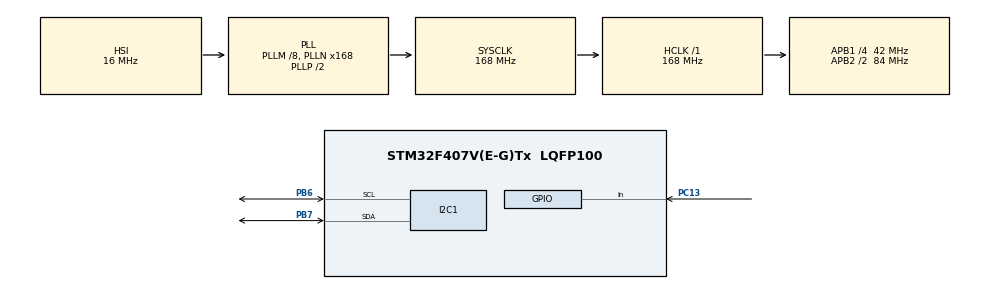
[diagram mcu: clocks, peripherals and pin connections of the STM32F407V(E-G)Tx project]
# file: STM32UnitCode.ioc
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Mcu.Family=STM32F4
Mcu.Name=STM32F407V(E-G)Tx
Mcu.Package=LQFP100
NVIC.PriorityGroup=NVIC_PRIORITYGROUP_4
PA13.Mode=Serial_Wire
PA13.Signal=SYS_JTMS-SWDIO
PA14.Mode=Serial_Wire
PA14.Signal=SYS_JTCK-SWCLK
PB6.Mode=I2C
PB6.Signal=I2C1_SCL
PB7.Mode=I2C
PB7.Signal=I2C1_SDA
PC13-ANTI_TAMP.Signal=GPIO_Input
PC14-OSC32_IN.Mode=LSE-External-Oscillator
PC14-OSC32_IN.Signal=RCC_OSC32_IN
PC15-OSC32_OUT.Mode=LSE-External-Oscillator
PC15-OSC32_OUT.Signal=RCC_OSC32_OUT
PH0-OSC_IN.Mode=HSE-External-Oscillator
PH0-OSC_IN.Signal=RCC_OSC_IN
PH1-OSC_OUT.Mode=HSE-External-Oscillator
PH1-OSC_OUT.Signal=RCC_OSC_OUT
ProjectManager.HeapSize=0x200
ProjectManager.StackSize=0x400
ProjectManager.TargetToolchain=Makefile
RCC.48MHZClocksFreq_Value=48000000
RCC.AHBFreq_Value=168000000
RCC.APB1CLKDivider=RCC_HCLK_DIV4
RCC.APB1Freq_Value=42000000
RCC.APB1TimFreq_Value=84000000
RCC.APB2CLKDivider=RCC_HCLK_DIV2
RCC.APB2Freq_Value=84000000
RCC.APB2TimFreq_Value=168000000
RCC.CortexFreq_Value=168000000
RCC.HCLKFreq_Value=168000000
RCC.HSE_VALUE=25000000
RCC.HSI_VALUE=16000000
RCC.PLLM=8
RCC.PLLN=168
RCC.PLLQ=7
RCC.SYSCLKFreq_VALUE=168000000
RCC.SYSCLKSource=RCC_SYSCLKSOURCE_PLLCLK
RCC.VCOOutputFreq_Value=336000000
board=custom

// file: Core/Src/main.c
/* USER CODE BEGIN Header */
/**
  ******************************************************************************
  * @file           : main.c
  * @brief          : Si5351A 硬件 I2C 驱动验证
  * @details        : 1. 上电后烧写 ClockBuilder Pro 导出配置
  *                      （OUT0=200MHz / OUT1=50MHz / OUT2=10MHz，共用 PLLA）
  *                   2. 之后每 3 秒在 CLK2 上循环切换 10M -> 25M -> 50M -> 100M
  *                      （动态改频走 PLLB，不影响 PLLA 上的 OUT0/OUT1）
  *
  *                   注意：Si5351 模块未连接时 I2C 会超时返回错误，
  *                   err 变量非 0，可用调试器查看定位。
  ******************************************************************************
  */
/* USER CODE END Header */

#include "main.h"
#include "i2c.h"
#include "gpio.h"

/* USER CODE BEGIN Includes */
#include "si5351.h"
/* USER CODE END Includes */

/* USER CODE BEGIN PV */
SI5351_HandleTypeDef hsi5351 = {0};
HAL_StatusTypeDef    err     = HAL_OK;
/* USER CODE END PV */

void SystemClock_Config(void);

int main(void)
{

  /* MCU Configuration--------------------------------------------------------*/

  /* Reset of all peripherals, Initializes the Flash interface and the Systick. */
  HAL_Init();

  /* Configure the system clock */
  SystemClock_Config();

  /* Initialize all configured peripherals */
  MX_GPIO_Init();
  MX_I2C1_Init();
  /* USER CODE BEGIN 2 */

  /* 1. Si5351 基础初始化：关闭所有输出 -> 驱动掉电 -> 晶振负载电容
        （addr/xtal_hz/xtal_load 填 0 用默认：0x60 / 25MHz / 10pF） */
  err = SI5351_Init(&hsi5351, &hi2c1);

  /* 2. 烧写 ClockBuilder Pro 导出配置（Si5351A-RevB-Registers.h）
        = 写 61 条寄存器 + PLL 复位 + 使能输出
        此后 OUT0=200MHz / OUT1=50MHz / OUT2=10MHz 立即输出 */
  if (err == HAL_OK)
      err = SI5351_LoadClockBuilderConfig(&hsi5351);

  /* 模块未连接/通信失败时 err != HAL_OK，停在这里便于调试定位 */
  if (err != HAL_OK)
  {
      while (1) { }
  }

  /* 动态改频演示用的频率表（CLK2 走 PLLB，不影响 PLLA 上的 OUT0/OUT1） */
  const int32_t demo_freq[] = { 10000000, 25000000, 50000000, 100000000 };
  uint8_t idx = 0;

  /* USER CODE END 2 */

  /* Infinite loop */
  while (1)
  {

    /* USER CODE BEGIN 3 */
      /* 3. 每 3 秒在 CLK2 上切换频率：10M -> 25M -> 50M -> 100M -> ... */
      err = SI5351_SetupCLK2(&hsi5351, demo_freq[idx], SI5351_DRIVE_8MA);
      if (err == HAL_OK)
          err = SI5351_EnableOutputs(&hsi5351, 0x07);   // 三路全部使能

      idx = (idx + 1) % (sizeof(demo_freq) / sizeof(demo_freq[0]));
      HAL_Delay(3000);
  }
  /* USER CODE END 3 */
}

void SystemClock_Config(void)
{
  RCC_OscInitTypeDef RCC_OscInitStruct = {0};
  RCC_ClkInitTypeDef RCC_ClkInitStruct = {0};

  /** Configure the main internal regulator output voltage
  */
  __HAL_RCC_PWR_CLK_ENABLE();
  __HAL_PWR_VOLTAGESCALING_CONFIG(PWR_REGULATOR_VOLTAGE_SCALE1);

  /** Initializes the RCC Oscillators according to the specified parameters
  * in the RCC_OscInitTypeDef structure.
  */
  RCC_OscInitStruct.OscillatorType = RCC_OSCILLATORTYPE_HSI;
  RCC_OscInitStruct.HSIState = RCC_HSI_ON;
  RCC_OscInitStruct.HSICalibrationValue = RCC_HSICALIBRATION_DEFAULT;
  RCC_OscInitStruct.PLL.PLLState = RCC_PLL_ON;
  RCC_OscInitStruct.PLL.PLLSource = RCC_PLLSOURCE_HSI;
  RCC_OscInitStruct.PLL.PLLM = 8;
  RCC_OscInitStruct.PLL.PLLN = 168;
  RCC_OscInitStruct.PLL.PLLP = RCC_PLLP_DIV2;
  RCC_OscInitStruct.PLL.PLLQ = 7;
  if (HAL_RCC_OscConfig(&RCC_OscInitStruct) != HAL_OK)
  {
    Error_Handler();
  }

  /** Initializes the CPU, AHB and APB buses clocks
  */
  RCC_ClkInitStruct.ClockType = RCC_CLOCKTYPE_HCLK|RCC_CLOCKTYPE_SYSCLK
                              |RCC_CLOCKTYPE_PCLK1|RCC_CLOCKTYPE_PCLK2;
  RCC_ClkInitStruct.SYSCLKSource = RCC_SYSCLKSOURCE_PLLCLK;
  RCC_ClkInitStruct.AHBCLKDivider = RCC_SYSCLK_DIV1;
  RCC_ClkInitStruct.APB1CLKDivider = RCC_HCLK_DIV4;
  RCC_ClkInitStruct.APB2CLKDivider = RCC_HCLK_DIV2;

  if (HAL_RCC_ClockConfig(&RCC_ClkInitStruct, FLASH_LATENCY_5) != HAL_OK)
  {
    Error_Handler();
  }
}

void Error_Handler(void)
{
  __disable_irq();
  while (1) { }
}
